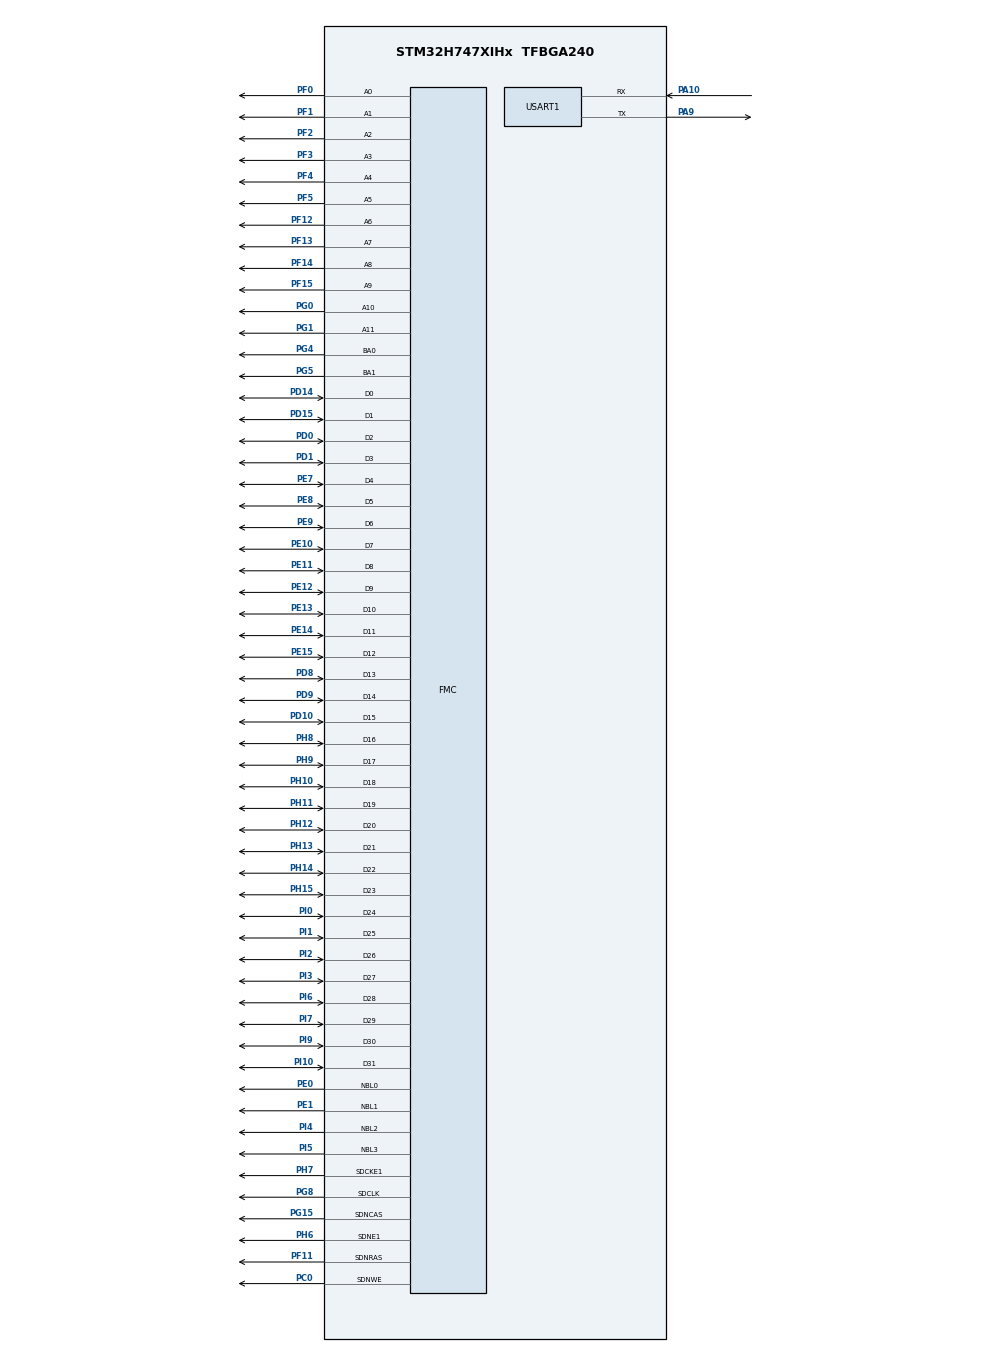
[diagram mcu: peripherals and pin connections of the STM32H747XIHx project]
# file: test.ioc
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CORTEX_M7.default_mode_Activation=1
CortexM4.IPs=CORTEX_M4\:I,FATFS_M4\:I,FREERTOS_M4\:I,IWDG2\:I,OPENAMP_M4\:I,PDM2PCM_M4\:I,PWR,RCC,RESMGR_UTILITY,SYS_M4\:I,USB_DEVICE_M4\:I,USB_HOST_M4\:I,VREFBUF,WWDG2\:I,GPIO,DMA,BDMA,MDMA,NVIC2\:I
CortexM7.IPs=CORTEX_M7\:I,FATFS_M7\:I,FREERTOS_M7\:I,IWDG1\:I,OPENAMP_M7\:I,PDM2PCM_M7\:I,PWR\:I,RCC\:I,RESMGR_UTILITY\:I,SYS\:I,USB_DEVICE_M7\:I,USB_HOST_M7\:I,VREFBUF\:I,WWDG1\:I,GPIO\:I,DMA\:I,BDMA\:I,MDMA\:I,NVIC1\:I,USART1\:I,FMC\:I
FMC.CASLatency2=FMC_SDRAM_CAS_LATENCY_2
FMC.ColumnBitsNumber2=FMC_SDRAM_COLUMN_BITS_NUM_9
FMC.ExitSelfRefreshDelay2=8
FMC.LoadToActiveDelay2=2
FMC.RCDDelay2=3
FMC.RPDelay1=3
FMC.RPDelay2=3
FMC.ReadPipeDelay1=FMC_SDRAM_RPIPE_DELAY_1
FMC.ReadPipeDelay2=FMC_SDRAM_RPIPE_DELAY_1
FMC.RowCycleDelay1=8
FMC.RowCycleDelay2=8
FMC.SDClockPeriod1=FMC_SDRAM_CLOCK_PERIOD_2
FMC.SDClockPeriod2=FMC_SDRAM_CLOCK_PERIOD_2
FMC.SelfRefreshTime2=6
FMC.WriteRecoveryTime2=3
Mcu.Family=STM32H7
Mcu.Name=STM32H747XIHx
Mcu.Package=TFBGA240
NVIC1.PriorityGroup=NVIC_PRIORITYGROUP_4
NVIC1.USART1_IRQn=true\:0\:0\:false\:false\:true\:true\:true\:true
NVIC2.PriorityGroup=NVIC_PRIORITYGROUP_4
PA10.Mode=Asynchronous
PA10.PinAttribute=CortexM7
PA10.Signal=USART1_RX
PA9.Mode=Asynchronous
PA9.PinAttribute=CortexM7
PA9.Signal=USART1_TX
PC0.PinAttribute=CortexM7
PC0.Signal=FMC_SDNWE
PD0.PinAttribute=CortexM7
PD0.Signal=FMC_D2_DA2
PD1.PinAttribute=CortexM7
PD1.Signal=FMC_D3_DA3
PD10.PinAttribute=CortexM7
PD10.Signal=FMC_D15_DA15
PD14.PinAttribute=CortexM7
PD14.Signal=FMC_D0_DA0
PD15.PinAttribute=CortexM7
PD15.Signal=FMC_D1_DA1
PD8.PinAttribute=CortexM7
PD8.Signal=FMC_D13_DA13
PD9.PinAttribute=CortexM7
PD9.Signal=FMC_D14_DA14
PE0.PinAttribute=CortexM7
PE0.Signal=FMC_NBL0
PE1.PinAttribute=CortexM7
PE1.Signal=FMC_NBL1
PE10.PinAttribute=CortexM7
PE10.Signal=FMC_D7_DA7
PE11.PinAttribute=CortexM7
PE11.Signal=FMC_D8_DA8
PE12.PinAttribute=CortexM7
PE12.Signal=FMC_D9_DA9
PE13.PinAttribute=CortexM7
PE13.Signal=FMC_D10_DA10
PE14.PinAttribute=CortexM7
PE14.Signal=FMC_D11_DA11
PE15.PinAttribute=CortexM7
PE15.Signal=FMC_D12_DA12
PE7.PinAttribute=CortexM7
PE7.Signal=FMC_D4_DA4
PE8.PinAttribute=CortexM7
PE8.Signal=FMC_D5_DA5
PE9.PinAttribute=CortexM7
PE9.Signal=FMC_D6_DA6
PF0.PinAttribute=CortexM7
PF0.Signal=FMC_A0
PF1.PinAttribute=CortexM7
PF1.Signal=FMC_A1
PF11.PinAttribute=CortexM7
PF11.Signal=FMC_SDNRAS
PF12.PinAttribute=CortexM7
PF12.Signal=FMC_A6
PF13.PinAttribute=CortexM7
PF13.Signal=FMC_A7
PF14.PinAttribute=CortexM7
PF14.Signal=FMC_A8
PF15.PinAttribute=CortexM7
PF15.Signal=FMC_A9
PF2.PinAttribute=CortexM7
PF2.Signal=FMC_A2
PF3.PinAttribute=CortexM7
PF3.Signal=FMC_A3
PF4.PinAttribute=CortexM7
PF4.Signal=FMC_A4
PF5.PinAttribute=CortexM7
PF5.Signal=FMC_A5
PG0.PinAttribute=CortexM7
PG0.Signal=FMC_A10
PG1.PinAttribute=CortexM7
PG1.Signal=FMC_A11
PG15.PinAttribute=CortexM7
PG15.Signal=FMC_SDNCAS
PG4.PinAttribute=CortexM7
PG4.Signal=FMC_A14_BA0
PG5.PinAttribute=CortexM7
PG5.Signal=FMC_A15_BA1
PG8.PinAttribute=CortexM7
PG8.Signal=FMC_SDCLK
PH10.PinAttribute=CortexM7
PH10.Signal=FMC_D18
PH11.PinAttribute=CortexM7
PH11.Signal=FMC_D19
PH12.PinAttribute=CortexM7
PH12.Signal=FMC_D20
PH13.PinAttribute=CortexM7
PH13.Signal=FMC_D21
PH14.PinAttribute=CortexM7
PH14.Signal=FMC_D22
PH15.PinAttribute=CortexM7
PH15.Signal=FMC_D23
PH6.Mode=SdramChipSelect2_2
PH6.PinAttribute=CortexM7
PH6.Signal=FMC_SDNE1
PH7.Mode=SdramChipSelect2_2
PH7.PinAttribute=CortexM7
PH7.Signal=FMC_SDCKE1
PH8.PinAttribute=CortexM7
PH8.Signal=FMC_D16
PH9.PinAttribute=CortexM7
PH9.Signal=FMC_D17
PI0.PinAttribute=CortexM7
PI0.Signal=FMC_D24
PI1.PinAttribute=CortexM7
PI1.Signal=FMC_D25
PI10.PinAttribute=CortexM7
PI10.Signal=FMC_D31
PI2.PinAttribute=CortexM7
PI2.Signal=FMC_D26
PI3.PinAttribute=CortexM7
PI3.Signal=FMC_D27
PI4.PinAttribute=CortexM7
PI4.Signal=FMC_NBL2
PI5.PinAttribute=CortexM7
PI5.Signal=FMC_NBL3
PI6.PinAttribute=CortexM7
PI6.Signal=FMC_D28
PI7.PinAttribute=CortexM7
PI7.Signal=FMC_D29
PI9.PinAttribute=CortexM7
PI9.Signal=FMC_D30
ProjectManager.HeapSize=M4-0x200,M7-0x200
ProjectManager.StackSize=M4-0x400,M7-0x400
ProjectManager.TargetToolchain=Makefile
RCC.ADCFreq_Value=129000000
RCC.APB1Freq_Value=120000000
RCC.APB2Freq_Value=120000000
RCC.APB3Freq_Value=120000000
RCC.APB4Freq_Value=120000000
RCC.CortexFreq_Value=480000000
RCC.D1PPRE=RCC_APB3_DIV2
RCC.D2PPRE1=RCC_APB1_DIV2
RCC.D2PPRE2=RCC_APB2_DIV2
RCC.D3PPRE=RCC_APB4_DIV2
RCC.DIVM1=4
RCC.DIVN1=60
RCC.HCLKFreq_Value=240000000
RCC.HPRE=RCC_HCLK_DIV2
RCC.PLL2FRACN=0
RCC.PLL3FRACN=0
RCC.PLLFRACN=0
RCC.SYSCLKFreq_VALUE=480000000
RCC.SYSCLKSource=RCC_SYSCLKSOURCE_PLLCLK
RCC.USBFreq_Value=480000000
SH.FMC_A0.0=FMC_A0,12b-sda2
SH.FMC_A1.0=FMC_A1,12b-sda2
SH.FMC_A10.0=FMC_A10,12b-sda2
SH.FMC_A11.0=FMC_A11,12b-sda2
SH.FMC_A14_BA0.0=FMC_BA0,FourSdramBanks2
SH.FMC_A15_BA1.0=FMC_BA1,FourSdramBanks2
SH.FMC_A2.0=FMC_A2,12b-sda2
SH.FMC_A3.0=FMC_A3,12b-sda2
SH.FMC_A4.0=FMC_A4,12b-sda2
SH.FMC_A5.0=FMC_A5,12b-sda2
SH.FMC_A6.0=FMC_A6,12b-sda2
SH.FMC_A7.0=FMC_A7,12b-sda2
SH.FMC_A8.0=FMC_A8,12b-sda2
SH.FMC_A9.0=FMC_A9,12b-sda2
SH.FMC_D0_DA0.0=FMC_D0,sd-32b-d2
SH.FMC_D10_DA10.0=FMC_D10,sd-32b-d2
SH.FMC_D11_DA11.0=FMC_D11,sd-32b-d2
SH.FMC_D12_DA12.0=FMC_D12,sd-32b-d2
SH.FMC_D13_DA13.0=FMC_D13,sd-32b-d2
SH.FMC_D14_DA14.0=FMC_D14,sd-32b-d2
SH.FMC_D15_DA15.0=FMC_D15,sd-32b-d2
SH.FMC_D16.0=FMC_D16,sd-32b-d2
SH.FMC_D17.0=FMC_D17,sd-32b-d2
SH.FMC_D18.0=FMC_D18,sd-32b-d2
SH.FMC_D19.0=FMC_D19,sd-32b-d2
SH.FMC_D1_DA1.0=FMC_D1,sd-32b-d2
SH.FMC_D20.0=FMC_D20,sd-32b-d2
SH.FMC_D21.0=FMC_D21,sd-32b-d2
SH.FMC_D22.0=FMC_D22,sd-32b-d2
SH.FMC_D23.0=FMC_D23,sd-32b-d2
SH.FMC_D24.0=FMC_D24,sd-32b-d2
SH.FMC_D25.0=FMC_D25,sd-32b-d2
SH.FMC_D26.0=FMC_D26,sd-32b-d2
SH.FMC_D27.0=FMC_D27,sd-32b-d2
SH.FMC_D28.0=FMC_D28,sd-32b-d2
SH.FMC_D29.0=FMC_D29,sd-32b-d2
SH.FMC_D2_DA2.0=FMC_D2,sd-32b-d2
SH.FMC_D30.0=FMC_D30,sd-32b-d2
SH.FMC_D31.0=FMC_D31,sd-32b-d2
SH.FMC_D3_DA3.0=FMC_D3,sd-32b-d2
SH.FMC_D4_DA4.0=FMC_D4,sd-32b-d2
SH.FMC_D5_DA5.0=FMC_D5,sd-32b-d2
SH.FMC_D6_DA6.0=FMC_D6,sd-32b-d2
SH.FMC_D7_DA7.0=FMC_D7,sd-32b-d2
SH.FMC_D8_DA8.0=FMC_D8,sd-32b-d2
SH.FMC_D9_DA9.0=FMC_D9,sd-32b-d2
SH.FMC_NBL0.0=FMC_NBL0,Sd4ByteEnable2
SH.FMC_NBL1.0=FMC_NBL1,Sd4ByteEnable2
SH.FMC_NBL2.0=FMC_NBL2,Sd4ByteEnable2
SH.FMC_NBL3.0=FMC_NBL3,Sd4ByteEnable2
SH.FMC_SDCLK.0=FMC_SDCLK,12b-sda2
SH.FMC_SDNCAS.0=FMC_SDNCAS,12b-sda2
SH.FMC_SDNRAS.0=FMC_SDNRAS,12b-sda2
SH.FMC_SDNWE.0=FMC_SDNWE,12b-sda2
SYS.userName=SYS_M7
USART1.VirtualMode-Asynchronous=VM_ASYNC
VP_SYS_M4_VS_Systick.Mode=SysTick
board=custom

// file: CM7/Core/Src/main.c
/* USER CODE BEGIN Header */
/**
 ******************************************************************************
 * @file           : main.c
 * @brief          : Main program body
 ******************************************************************************
 * @attention
 *
 * Copyright (c) 2026 STMicroelectronics.
 * All rights reserved.
 *
 * This software is licensed under terms that can be found in the LICENSE file
 * in the root directory of this software component.
 * If no LICENSE file comes with this software, it is provided AS-IS.
 *
 ******************************************************************************
 */
/* USER CODE END Header */
#include "main.h"
#include "usart.h"
#include "gpio.h"
#include "fmc.h"

/* USER CODE BEGIN Includes */
#include <stdio.h>
#include "bsp_sys.h"
#include "mpu.h"
#include "sdram.h"
/* USER CODE END Includes */

/* USER CODE BEGIN PD */

#ifndef HSEM_ID_0
#define HSEM_ID_0 (0U) /* HW semaphore 0*/
#endif

/* USER CODE END PD */

void SystemClock_Config(void);
static void MPU_Config(void);

int main(void)
{

  /* USER CODE BEGIN 1 */
  bsp_cache_enable(); // 打开指令/数据Cache，提升访问速度（避免SDRAM访问性能过低）
  /* USER CODE END 1 */
/* USER CODE BEGIN Boot_Mode_Sequence_0 */
  int32_t timeout;
/* USER CODE END Boot_Mode_Sequence_0 */

  /* MPU Configuration--------------------------------------------------------*/
  MPU_Config();

/* USER CODE BEGIN Boot_Mode_Sequence_1 */
  /* Wait until CPU2 boots and enters in stop mode or timeout*/
  timeout = 0xFFFF;
  while ((__HAL_RCC_GET_FLAG(RCC_FLAG_D2CKRDY) != RESET) && (timeout-- > 0))
    ;
  if (timeout < 0)
  {
    Error_Handler();
  }
/* USER CODE END Boot_Mode_Sequence_1 */
  /* MCU Configuration--------------------------------------------------------*/

  /* Reset of all peripherals, Initializes the Flash interface and the Systick. */
  HAL_Init();

  /* Configure the system clock */
  SystemClock_Config();
/* USER CODE BEGIN Boot_Mode_Sequence_2 */
  /* When system initialization is finished, Cortex-M7 will release Cortex-M4 by means of
  HSEM notification */
  /*HW semaphore Clock enable*/
  __HAL_RCC_HSEM_CLK_ENABLE();
  /*Take HSEM */
  HAL_HSEM_FastTake(HSEM_ID_0);
  /*Release HSEM in order to notify the CPU2(CM4)*/
  HAL_HSEM_Release(HSEM_ID_0, 0);
  /* wait until CPU2 wakes up from stop mode */
  timeout = 0xFFFF;
  while ((__HAL_RCC_GET_FLAG(RCC_FLAG_D2CKRDY) == RESET) && (timeout-- > 0))
    ;
  if (timeout < 0)
  {
    Error_Handler();
  }
/* USER CODE END Boot_Mode_Sequence_2 */

  /* Initialize all configured peripherals */
  MX_GPIO_Init();
  MX_USART1_UART_Init();
  mpu_memory_protection(); // 配置MPU：把SDRAM这段外部存储设置为合适的Cache策略（避免DCache导致读回不一致）
  MX_FMC_Init();
  /* USER CODE BEGIN 2 */
  sdram_init();

  printf("\r\n\r\nSDRAM TEST\r\n");
  sdram_test(); // SDRAM测试：用递增pattern跨地址写入，再按相同步长读回，找出开始失真的位置来估算容量
  printf("SDRAM test done.\r\n");
  /* USER CODE END 2 */

  /* Infinite loop */
  while (1)
  {

    /* USER CODE BEGIN 3 */
    HAL_Delay(1000);
  }
  /* USER CODE END 3 */
}

void SystemClock_Config(void)
{
  RCC_OscInitTypeDef RCC_OscInitStruct = {0};
  RCC_ClkInitTypeDef RCC_ClkInitStruct = {0};

  /** Supply configuration update enable
  */
  HAL_PWREx_ConfigSupply(PWR_LDO_SUPPLY);

  /** Configure the main internal regulator output voltage
  */
  __HAL_PWR_VOLTAGESCALING_CONFIG(PWR_REGULATOR_VOLTAGE_SCALE0);

  while(!__HAL_PWR_GET_FLAG(PWR_FLAG_VOSRDY)) {}

  /** Initializes the RCC Oscillators according to the specified parameters
  * in the RCC_OscInitTypeDef structure.
  */
  RCC_OscInitStruct.OscillatorType = RCC_OSCILLATORTYPE_HSI;
  RCC_OscInitStruct.HSIState = RCC_HSI_DIV1;
  RCC_OscInitStruct.HSICalibrationValue = RCC_HSICALIBRATION_DEFAULT;
  RCC_OscInitStruct.PLL.PLLState = RCC_PLL_ON;
  RCC_OscInitStruct.PLL.PLLSource = RCC_PLLSOURCE_HSI;
  RCC_OscInitStruct.PLL.PLLM = 4;
  RCC_OscInitStruct.PLL.PLLN = 60;
  RCC_OscInitStruct.PLL.PLLP = 2;
  RCC_OscInitStruct.PLL.PLLQ = 2;
  RCC_OscInitStruct.PLL.PLLR = 2;
  RCC_OscInitStruct.PLL.PLLRGE = RCC_PLL1VCIRANGE_3;
  RCC_OscInitStruct.PLL.PLLVCOSEL = RCC_PLL1VCOWIDE;
  RCC_OscInitStruct.PLL.PLLFRACN = 0;
  if (HAL_RCC_OscConfig(&RCC_OscInitStruct) != HAL_OK)
  {
    Error_Handler();
  }

  /** Initializes the CPU, AHB and APB buses clocks
  */
  RCC_ClkInitStruct.ClockType = RCC_CLOCKTYPE_HCLK|RCC_CLOCKTYPE_SYSCLK
                              |RCC_CLOCKTYPE_PCLK1|RCC_CLOCKTYPE_PCLK2
                              |RCC_CLOCKTYPE_D3PCLK1|RCC_CLOCKTYPE_D1PCLK1;
  RCC_ClkInitStruct.SYSCLKSource = RCC_SYSCLKSOURCE_PLLCLK;
  RCC_ClkInitStruct.SYSCLKDivider = RCC_SYSCLK_DIV1;
  RCC_ClkInitStruct.AHBCLKDivider = RCC_HCLK_DIV2;
  RCC_ClkInitStruct.APB3CLKDivider = RCC_APB3_DIV2;
  RCC_ClkInitStruct.APB1CLKDivider = RCC_APB1_DIV2;
  RCC_ClkInitStruct.APB2CLKDivider = RCC_APB2_DIV2;
  RCC_ClkInitStruct.APB4CLKDivider = RCC_APB4_DIV2;

  if (HAL_RCC_ClockConfig(&RCC_ClkInitStruct, FLASH_LATENCY_4) != HAL_OK)
  {
    Error_Handler();
  }
}

 /* MPU Configuration */

void MPU_Config(void)
{
  MPU_Region_InitTypeDef MPU_InitStruct = {0};

  /* Disables the MPU */
  HAL_MPU_Disable();

  /** Initializes and configures the Region and the memory to be protected
  */
  MPU_InitStruct.Enable = MPU_REGION_ENABLE;
  MPU_InitStruct.Number = MPU_REGION_NUMBER0;
  MPU_InitStruct.BaseAddress = 0x0;
  MPU_InitStruct.Size = MPU_REGION_SIZE_4GB;
  MPU_InitStruct.SubRegionDisable = 0x87;
  MPU_InitStruct.TypeExtField = MPU_TEX_LEVEL0;
  MPU_InitStruct.AccessPermission = MPU_REGION_NO_ACCESS;
  MPU_InitStruct.DisableExec = MPU_INSTRUCTION_ACCESS_DISABLE;
  MPU_InitStruct.IsShareable = MPU_ACCESS_SHAREABLE;
  MPU_InitStruct.IsCacheable = MPU_ACCESS_NOT_CACHEABLE;
  MPU_InitStruct.IsBufferable = MPU_ACCESS_NOT_BUFFERABLE;

  HAL_MPU_ConfigRegion(&MPU_InitStruct);
  /* Enables the MPU */
  HAL_MPU_Enable(MPU_PRIVILEGED_DEFAULT);

}

void Error_Handler(void)
{
  __disable_irq();
  while (1)
  {
  }
}
